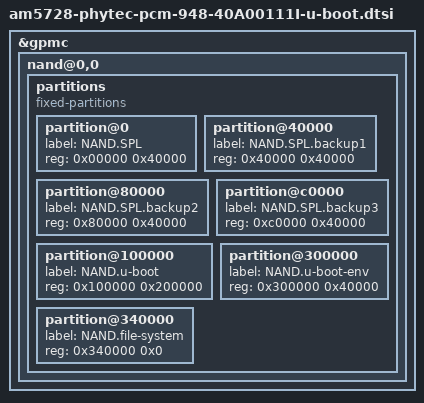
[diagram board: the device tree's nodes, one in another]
// SPDX-License-Identifier: GPL-2.0
/*
 * Copyright (C) 2024 PHYTEC Messtechnik GmbH
 * Author: Primoz Fiser <primoz.fiser@norik.com>
 */

#include "am57xx-phytec-pcm-948-u-boot.dtsi"

&gpmc {
	nand@0,0 {
		partitions {
			compatible = "fixed-partitions";
			#address-cells = <1>;
			#size-cells = <1>;
			partition@0 {
				label = "NAND.SPL";
				reg = <0x00000 0x40000>;
			};
			partition@40000 {
				label = "NAND.SPL.backup1";
				reg = <0x40000 0x40000>;
			};
			partition@80000 {
				label = "NAND.SPL.backup2";
				reg = <0x80000 0x40000>;
			};
			partition@c0000 {
				label = "NAND.SPL.backup3";
				reg = <0xc0000 0x40000>;
			};
			partition@100000 {
				label = "NAND.u-boot";
				reg = <0x100000 0x200000>;
			};
			partition@300000 {
				label = "NAND.u-boot-env";
				reg = <0x300000 0x40000>;
			};
			partition@340000 {
				label = "NAND.file-system";
				reg = <0x340000 0x0>;
			};
		};
	};
};
